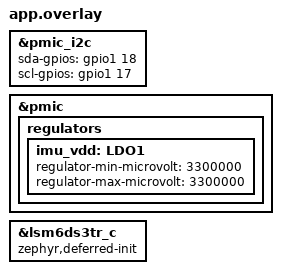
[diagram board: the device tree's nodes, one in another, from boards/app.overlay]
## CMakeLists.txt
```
cmake_minimum_required(VERSION 3.20.0)
find_package(Zephyr REQUIRED HINTS $ENV{ZEPHYR_BASE})

project(imu_stm_lsm6dsl)

target_sources(app PRIVATE src/main.c)
```

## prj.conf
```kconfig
CONFIG_STDOUT_CONSOLE=y

CONFIG_LOG=y
CONFIG_LOG_BACKEND_UART=y
CONFIG_LOG_BACKEND_SHOW_COLOR=n
CONFIG_LOG_DEFAULT_LEVEL=3
CONFIG_MAIN_STACK_SIZE=2048
CONFIG_SYSTEM_WORKQUEUE_STACK_SIZE=2048
CONFIG_GPIO=y
CONFIG_I2C=y
CONFIG_MFD=y
CONFIG_REGULATOR=y
CONFIG_SENSOR=y
CONFIG_LSM6DSL=y
CONFIG_LSM6DSL_TRIGGER_GLOBAL_THREAD=y
CONFIG_CBPRINTF_FP_SUPPORT=y
CONFIG_CBPRINTF_COMPLETE=y
```

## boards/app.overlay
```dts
&pmic_i2c {
        sda-gpios = <&gpio1 18 GPIO_ACTIVE_HIGH>;
        scl-gpios = <&gpio1 17 GPIO_ACTIVE_HIGH>;
        status = "okay";
};

&pmic {
        regulators {
                imu_vdd: LDO1 {
                        regulator-min-microvolt = <3300000>;
                        regulator-max-microvolt = <3300000>;
                        /*
                         * Do not enable LDO1 during regulator driver init: the
                         * nPM1300 sits on gpio-i2c, which may not be ready yet.
                         * main() enables this rail before deferred IMU init.
                         * Use /delete-property/ so this also overrides board
                         * revisions that define regulator-boot-on themselves.
                         */
                        /delete-property/ regulator-boot-on;
                };
        };
};

&lsm6ds3tr_c {
        zephyr,deferred-init;
};
```

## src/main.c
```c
#include <errno.h>
#include <zephyr/kernel.h>
#include <zephyr/device.h>
#include <zephyr/drivers/sensor.h>
#include <zephyr/drivers/regulator.h>
#include <zephyr/logging/log.h>

LOG_MODULE_REGISTER(zephyr_imu, LOG_LEVEL_INF);

#define IMU_NODE DT_ALIAS(imu0)

/*
 * nrf54lm20a needs power_en (fixed regulator on gpio1.12) and imu_vdd
 * (PMIC NPM1300 LDO1) enabled before the IMU can be used.
 * nrf54l15 has pdm_imu_pwr with regulator-boot-on; power is already on.
 */
#if defined(DT_N_NODELABEL_power_en)
static const struct device *const power_en_dev =
    DEVICE_DT_GET(DT_NODELABEL(power_en));
#endif

#if defined(DT_N_NODELABEL_imu_vdd)
static const struct device *const imu_vdd_dev =
    DEVICE_DT_GET(DT_NODELABEL(imu_vdd));
#endif

static int enable_imu_power(void)
{
#if defined(DT_N_NODELABEL_power_en) || defined(DT_N_NODELABEL_imu_vdd)
    int ret;
#endif

#if defined(DT_N_NODELABEL_power_en)
    if (!device_is_ready(power_en_dev)) {
        LOG_ERR("power_en regulator is not ready");
        return -ENODEV;
    }
    ret = regulator_enable(power_en_dev);
    if (ret < 0 && ret != -EALREADY) {
        LOG_ERR("Failed to enable power_en: %d", ret);
        return ret;
    }
#endif

#if defined(DT_N_NODELABEL_imu_vdd)
    if (!device_is_ready(imu_vdd_dev)) {
        LOG_ERR("imu_vdd regulator is not ready");
        return -ENODEV;
    }
    ret = regulator_enable(imu_vdd_dev);
    if (ret < 0 && ret != -EALREADY) {
        LOG_ERR("Failed to enable imu_vdd: %d", ret);
        return ret;
    }
#endif

#if defined(DT_N_NODELABEL_power_en) || defined(DT_N_NODELABEL_imu_vdd)
    /* Wait for power rail to stabilize */
    k_sleep(K_MSEC(20));
#endif

    return 0;
}

static inline float out_ev(struct sensor_value *val)
{
    return (val->val1 + (float)val->val2 / 1000000);
}

static void fetch_and_display(const struct device *dev)
{
    struct sensor_value x, y, z;
    static int trig_cnt;

    trig_cnt++;

    /* lsm6dsl accel */
    sensor_sample_fetch_chan(dev, SENSOR_CHAN_ACCEL_XYZ);
    sensor_channel_get(dev, SENSOR_CHAN_ACCEL_X, &x);
    sensor_channel_get(dev, SENSOR_CHAN_ACCEL_Y, &y);
    sensor_channel_get(dev, SENSOR_CHAN_ACCEL_Z, &z);

    LOG_INF("accel x:%f m/s^2 y:%f m/s^2 z:%f m/s^2",
            (double)out_ev(&x), (double)out_ev(&y), (double)out_ev(&z));

    /* lsm6dsl gyro */
    sensor_sample_fetch_chan(dev, SENSOR_CHAN_GYRO_XYZ);
    sensor_channel_get(dev, SENSOR_CHAN_GYRO_X, &x);
    sensor_channel_get(dev, SENSOR_CHAN_GYRO_Y, &y);
    sensor_channel_get(dev, SENSOR_CHAN_GYRO_Z, &z);

    LOG_INF("gyro x:%f rad/s y:%f rad/s z:%f rad/s",
            (double)out_ev(&x), (double)out_ev(&y), (double)out_ev(&z));

    LOG_INF("trig_cnt:%d", trig_cnt);
}

static int set_sampling_freq(const struct device *dev)
{
    int ret = 0;
    struct sensor_value odr_attr;

    /* set accel/gyro sampling frequency to 12.5 Hz */
    odr_attr.val1 = 12;
    odr_attr.val2 = 500000;

    ret = sensor_attr_set(dev, SENSOR_CHAN_ACCEL_XYZ,
            SENSOR_ATTR_SAMPLING_FREQUENCY, &odr_attr);
    if (ret != 0) {
        LOG_ERR("Cannot set sampling frequency for accelerometer.");
        return ret;
    }

    ret = sensor_attr_set(dev, SENSOR_CHAN_GYRO_XYZ,
            SENSOR_ATTR_SAMPLING_FREQUENCY, &odr_attr);
    if (ret != 0) {
        LOG_ERR("Cannot set sampling frequency for gyro.");
        return ret;
    }

    return 0;
}

#ifdef CONFIG_LSM6DSL_TRIGGER
static void trigger_handler(const struct device *dev,
                const struct sensor_trigger *trig)
{
    fetch_and_display(dev);
}

static void test_trigger_mode(const struct device *dev)
{
    struct sensor_trigger trig;

    if (set_sampling_freq(dev) != 0) {
        return;
    }

    trig.type = SENSOR_TRIG_DATA_READY;
    trig.chan = SENSOR_CHAN_ACCEL_XYZ;

    if (sensor_trigger_set(dev, &trig, trigger_handler) != 0) {
        LOG_ERR("Could not set sensor type and channel");
        return;
    }

    while (1) {
        k_sleep(K_MSEC(1000));
    }
}

#else
static void test_polling_mode(const struct device *dev)
{
    if (set_sampling_freq(dev) != 0) {
        return;
    }

    while (1) {
        fetch_and_display(dev);
        k_sleep(K_MSEC(1000));
    }
}
#endif

int main(void)
{
    const struct device *const dev = DEVICE_DT_GET(IMU_NODE);
    int ret;

    /* On nrf54lm20a, enable power_en + imu_vdd before accessing IMU.
     * On nrf54l15, these nodes don't exist; function returns immediately.
     */
    ret = enable_imu_power();
    if (ret < 0) {
        LOG_ERR("Failed to enable IMU power: %d", ret);
        return 0;
    }

    /* On nrf54lm20a, IMU has zephyr,deferred-init; must init manually.
     * On nrf54l15, device auto-inits at boot; device_is_ready() is true.
     */
    if (!device_is_ready(dev)) {
        ret = device_init(dev);
        if (ret < 0 && ret != -EALREADY) {
            LOG_ERR("Failed to initialize %s: %d", dev->name, ret);
            return 0;
        }
    }

    if (!device_is_ready(dev)) {
        LOG_ERR("%s: device not ready.", dev->name);
        return 0;
    }

#ifdef CONFIG_LSM6DSL_TRIGGER
    LOG_INF("Testing LSM6DSL sensor in trigger mode.");
    test_trigger_mode(dev);
#else
    LOG_INF("Testing LSM6DSL sensor in polling mode.");
    test_polling_mode(dev);
#endif
    return 0;
}
```
